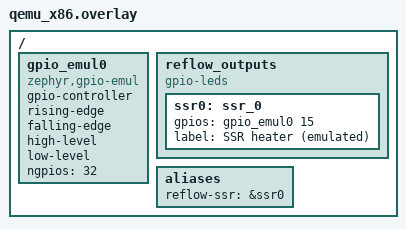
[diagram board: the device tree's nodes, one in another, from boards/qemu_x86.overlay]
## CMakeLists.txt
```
# SPDX-License-Identifier: Apache-2.0

cmake_minimum_required(VERSION 3.20.0)

# Same reason as tests/boot: reuse the application's Kconfig instead of
# restating the CONFIG_REFLOW_* symbols the control core reads. The test then
# runs against the periods, gains and cut-out the firmware actually ships with.
set(KCONFIG_ROOT ${CMAKE_CURRENT_SOURCE_DIR}/../../Kconfig)

find_package(Zephyr REQUIRED HINTS $ENV{ZEPHYR_BASE})
project(reflow_controller_tests LANGUAGES C)

set(SRC  ${CMAKE_CURRENT_SOURCE_DIR}/../../src)
set(CORE ${SRC}/core)

# The whole control path, shipped as-is, with one substitution: temp_fake.c
# takes the place of ${CORE}/temp.c. That file is the only one that talks to the
# MAX6675, and on a simulated platform there is no MAX6675 behind the emulated
# SPI bus - reflow_temp_init() fails, the controller latches FAULT_SENSOR and no
# run ever starts. Swapping it at link time keeps controller.c, heater.c, pid.c,
# profile.c and tempguard.c exactly as they are flashed.
target_sources(app PRIVATE
  src/main.c
  src/temp_fake.c
  ${CORE}/controller.c
  ${CORE}/heater.c
  ${CORE}/pid.c
  ${CORE}/profile.c
  ${CORE}/tempguard.c
)
target_include_directories(app PRIVATE ${SRC} ${CORE})
```

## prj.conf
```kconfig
CONFIG_ZTEST=y
CONFIG_ZBUS=y
CONFIG_GPIO=y
CONFIG_GPIO_EMUL=y

# The optional features are not in this image: the point of the suite is the
# control core on its own, and their Kconfig dependencies would pull in
# subsystems (display, networking) this test has no board for.
CONFIG_REFLOW_SHELL=n
CONFIG_REFLOW_UI_DISPLAY=n
CONFIG_REFLOW_UI_INPUT=n
CONFIG_REFLOW_NET=n
```

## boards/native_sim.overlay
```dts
/*
 * SPDX-License-Identifier: Apache-2.0
 *
 * SIMULATION ONLY -- nothing here describes hardware.
 *
 * native_sim already provides a GPIO emulator as gpio0, so unlike the qemu_x86
 * overlay next to this one there is no controller to declare: only the SSR node
 * heater.c needs, and its alias.
 *
 * There is deliberately no thermocouple node. The application's
 * boards/native_sim.overlay declares one, and its own comment records why that
 * is not enough: the emulated bus has no MAX6675 behind it, so
 * reflow_temp_init() fails and the controller latches FAULT_SENSOR before a run
 * can start. This suite links temp_fake.c instead, and the sample comes from
 * the test.
 *
 * native_sim does not run on Windows (PROCESSO.md section 10), which is why the
 * qemu_x86 overlay exists as well. Both platforms build the same source.
 */

#include <zephyr/dt-bindings/gpio/gpio.h>

/ {
	reflow_outputs {
		compatible = "gpio-leds";

		ssr0: ssr_0 {
			gpios = <&gpio0 15 GPIO_ACTIVE_HIGH>;
			label = "SSR heater (emulated)";
		};
	};

	aliases {
		reflow-ssr = &ssr0;
	};
};
```

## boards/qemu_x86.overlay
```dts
/*
 * SPDX-License-Identifier: Apache-2.0
 *
 * SIMULATION ONLY -- nothing here describes hardware.
 *
 * Only the SSR gate is declared. There is deliberately no thermocouple node:
 * src/core/temp.c is not in this image, tests/controller/src/temp_fake.c is,
 * and the whole point of the suite is that the reading comes from the test
 * instead of from a bus.
 *
 * qemu_x86 has no GPIO controller of its own, so the emulator is declared here.
 * Pin 15 and GPIO_ACTIVE_HIGH mirror tests/boot and the application overlays.
 */

#include <zephyr/dt-bindings/gpio/gpio.h>

/ {
	gpio_emul0: gpio_emul0 {
		compatible = "zephyr,gpio-emul";
		gpio-controller;
		rising-edge;
		falling-edge;
		high-level;
		low-level;
		#gpio-cells = <2>;
		ngpios = <32>;
		status = "okay";
	};

	reflow_outputs {
		compatible = "gpio-leds";

		ssr0: ssr_0 {
			gpios = <&gpio_emul0 15 GPIO_ACTIVE_HIGH>;
			label = "SSR heater (emulated)";
		};
	};

	aliases {
		reflow-ssr = &ssr0;
	};
};
```

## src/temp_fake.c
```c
/*
 * SPDX-License-Identifier: Apache-2.0
 *
 * See temp_fake.h. This mirrors the shape of src/core/temp.c — plausibility
 * window, then reflow_spike_filter(), then both the filtered and the raw value
 * out — with the sensor driver replaced by a value the test writes.
 *
 * Keeping the guard rails here rather than returning the injected value
 * straight through is the point: a fake that skipped the filter would let a
 * controller test pass while the real path suppressed the same sample.
 */

#include <errno.h>

#include <zephyr/kernel.h>

#include "temp.h"
#include "tempguard.h"
#include "temp_fake.h"

/*
 * Same window as temp.c, copied rather than shared: the constants are private to
 * temp.c and hoisting them into temp.h is a production change, out of scope here.
 *
 * Say the cost out loud, because no test catches it: widen or narrow the window in
 * temp.c and this fake keeps the old one, silently. Nothing goes red. Unlike the
 * spike filter below -- which calls the real tempguard.c precisely so it cannot
 * drift -- this pair is kept honest by whoever edits temp.c remembering to look
 * here. If the window ever becomes a decision rather than a sanity check, move it
 * to tempguard.c and delete these two lines.
 */
#define TEMP_MIN_MC (-20000)
#define TEMP_MAX_MC (400000)

/* Room temperature: what a healthy sensor reads with the oven cold. */
#define FAKE_IDLE_MC 25000

static struct k_spinlock lock;

static struct {
	struct reflow_spike spike;
	int32_t raw_mc;
	int read_err;
	uint32_t reads;
} fake = {
	.raw_mc = FAKE_IDLE_MC,
};

void reflow_temp_fake_reset(void)
{
	k_spinlock_key_t key = k_spin_lock(&lock);
	int32_t discard;

	reflow_spike_reset(&fake.spike);
	fake.raw_mc = FAKE_IDLE_MC;
	fake.read_err = 0;
	fake.reads = 0;

	/*
	 * Prime the filter with the idle reading, so the fake starts out as a
	 * sensor that has been reading room temperature rather than one that
	 * has never been read. It matters: reflow_spike_filter() accepts its
	 * first sample unconditionally, having nothing to compare against, so
	 * an unprimed fake would swallow the very first injected step -- and a
	 * test that means to exercise the spike rejector would quietly exercise
	 * nothing.
	 */
	(void)reflow_spike_filter(&fake.spike, FAKE_IDLE_MC, &discard);
	k_spin_unlock(&lock, key);
}

void reflow_temp_fake_set_raw_mc(int32_t raw_mc)
{
	k_spinlock_key_t key = k_spin_lock(&lock);

	fake.raw_mc = raw_mc;
	k_spin_unlock(&lock, key);
}

void reflow_temp_fake_fail(int err)
{
	k_spinlock_key_t key = k_spin_lock(&lock);

	fake.read_err = err;
	k_spin_unlock(&lock, key);
}

uint32_t reflow_temp_fake_reads(void)
{
	k_spinlock_key_t key = k_spin_lock(&lock);
	uint32_t n = fake.reads;

	k_spin_unlock(&lock, key);
	return n;
}

/*
 * Always succeeds, and there is no knob to make it fail. The control thread
 * runs this from K_THREAD_DEFINE at boot, before any ztest body -- and before a
 * `setup` hook too -- so an injected init failure could never be set in time to
 * be observed. Covering the no-thermocouple-at-boot path needs the controller to
 * retry initialisation, which is a production change and belongs to its own
 * issue, not to a knob here that looks usable and is not.
 */
int reflow_temp_init(void)
{
	k_spinlock_key_t key = k_spin_lock(&lock);

	reflow_spike_reset(&fake.spike);
	k_spin_unlock(&lock, key);

	return 0;
}

int reflow_temp_read(int32_t *temp_mc, int32_t *raw_mc)
{
	k_spinlock_key_t key = k_spin_lock(&lock);
	int32_t raw, filtered;
	int ret = 0;

	fake.reads++;

	if (fake.read_err != 0) {
		ret = fake.read_err;
		goto out;
	}

	raw = fake.raw_mc;
	if (raw < TEMP_MIN_MC || raw > TEMP_MAX_MC) {
		ret = -ERANGE;
		goto out;
	}

	(void)reflow_spike_filter(&fake.spike, raw, &filtered);

	*temp_mc = filtered;
	if (raw_mc != NULL) {
		*raw_mc = raw;
	}

out:
	k_spin_unlock(&lock, key);
	return ret;
}
```

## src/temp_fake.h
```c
/*
 * SPDX-License-Identifier: Apache-2.0
 *
 * Injectable thermocouple for the controller suite (RFO-G06).
 *
 * This file provides the temp.h contract in place of src/core/temp.c, so
 * controller.c can be linked into a test image with no MAX6675 and no SPI
 * behind it. The test writes the sample; the controller reads it through
 * exactly the same two functions it calls on hardware.
 *
 * It is deliberately NOT a Kconfig option in the firmware. A production build
 * able to read a made-up temperature is a foot-gun on a mains heater: the
 * substitution happens at link time, in the test's CMakeLists, so no shipped
 * image can contain it.
 */

#ifndef REFLOW_TEMP_FAKE_H_
#define REFLOW_TEMP_FAKE_H_

#include <stdint.h>

/* Healthy sensor at 25 degC, no injected errors, spike history forgotten. */
void reflow_temp_fake_reset(void);

/*
 * The raw sample the next reads return, in milli-degC. It goes through the
 * same plausibility window and the same reflow_spike_filter() that temp.c
 * uses, so a jump larger than REFLOW_SPIKE_MAX_STEP_MC is suppressed here for
 * the same number of samples it would be suppressed on hardware. That is what
 * makes "stuck reading" (RFO-B05) reproducible instead of hand-waved: the test
 * injects a real step, the filter does the sticking.
 */
void reflow_temp_fake_set_raw_mc(int32_t raw_mc);

/*
 * Make reflow_temp_read() return this errno instead of a sample; 0 stops
 * failing. -ENOENT is what the MAX6675 driver reports for an open
 * thermocouple, -EIO what a failed SPI transfer reports.
 */
void reflow_temp_fake_fail(int err);

/* Make reflow_temp_init() return this errno; 0 stops failing. */
void reflow_temp_fake_fail_init(int err);

/* Number of reflow_temp_read() calls since the last reset. */
uint32_t reflow_temp_fake_reads(void);

#endif /* REFLOW_TEMP_FAKE_H_ */
```
